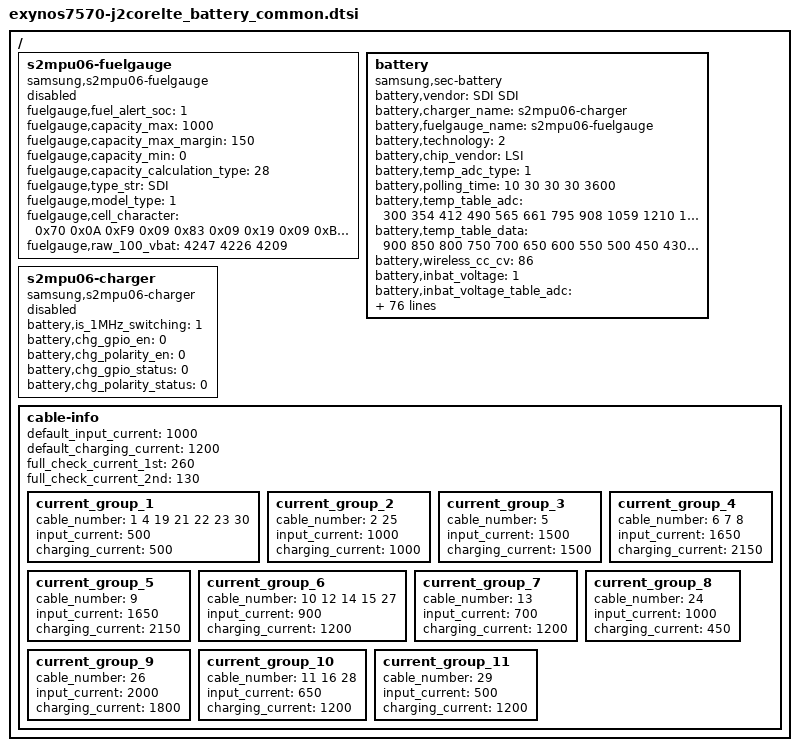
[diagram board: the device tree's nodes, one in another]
/*
 * SAMSUNG UNIVERSAL7570 board device tree source
 *
 * Copyright (c) 2018 Samsung Electronics Co., Ltd.
 *		http://www.samsung.com
 *
 * This program is free software; you can redistribute it and/or modify
 * it under the terms of the GNU General Public License version 2 as
 * published by the Free Software Foundation.
*/

/ {
	s2mpu06-fuelgauge {
		status = "disable";
		compatible = "samsung,s2mpu06-fuelgauge";
		fuelgauge,fuel_alert_soc = <1>;
		fuelgauge,capacity_max = <1000>;
		fuelgauge,capacity_max_margin = <150>;
		fuelgauge,capacity_min = <0>;
		fuelgauge,capacity_calculation_type = <28>;
		fuelgauge,type_str = "SDI";
		fuelgauge,model_type = <1>;
		fuelgauge,cell_character = < 
				/* 4.30V Cell character*/
				/* Cell character 0 0x34 ~ 0xD7 */
				0x70 0x0A 0xF9 0x09 0x83 0x09 0x19 0x09 0xB3 0x08
				0x5A 0x08 0xE6 0x07 0xAE 0x07 0x67 0x07 0xFE 0x06
				0xBB 0x06 0x8F 0x06 0x6C 0x06 0x52 0x06 0x3D 0x06
				0x29 0x06 0x01 0x06 0xD6 0x05 0x95 0x05 0x81 0x05
				0x59 0x04 0x2B 0x03 0x6A 0x08 0x00 0x08 0x95 0x07
				0x2B 0x07 0xC0 0x06 0x56 0x06 0xEB 0x05 0x81 0x05
				0x16 0x05 0xAC 0x04 0x41 0x04 0xD7 0x03 0x6C 0x03
				0x02 0x03 0x97 0x02 0x2D 0x02 0xC2 0x01 0x58 0x01
				0xED 0x00 0x83 0x00 0x18 0x00 0xF5 0x0F 0xFE 0x29
				0xDC 0x29 0x8A 0x29 0x4D 0x29 0x28 0x1F 0x23 0x10
				0x21 0x21 0x14 0x21 0xE9 0xF7 0xE6 0xF7 0xD3 0xDE
				0xCA 0xD4 0xD3 0xD4 0x40 0x80 0x26 0x33 0x26 0x40
				0x26 0x5C 0x26 0x5C 0x26 0x5C 0xFF 0xFF 0x02 0x05
				0x14 0x0B 0x03 0x12 0x06 0x1C 0x0C 0x1C 0x10 0x1C
				0x1F 0x1F 0x40 0x40 0x40 0x40 0x40 0x40 0x41 0x41
				0x40 0x40 0x40 0x41 0x42 0x43 0x44 0x46 0x47 0x4B
				0x51 0x62 0x88 0x80

				/* Cell character 1, 0x0F ~ 0x13 */
				0xEC 0x28 0x0A 0x00 0x00

				/* 4.28V Cell character*/
				/* Cell character 0, 0x34 ~ 0xD7 */
				0x3E 0x0A 0xCF 0x09 0x60 0x09 0xFC 0x08 0xA3 0x08
				0x3B 0x08 0xDF 0x07 0xA8 0x07 0x66 0x07 0x00 0x07
				0xBE 0x06 0x93 0x06 0x71 0x06 0x56 0x06 0x40 0x06
				0x33 0x06 0x11 0x06 0xED 0x05 0xB8 0x05 0x88 0x05
				0x60 0x05 0x20 0x03 0x68 0x08 0x00 0x08 0x98 0x07
				0x2F 0x07 0xC7 0x06 0x5F 0x06 0xF6 0x05 0x8E 0x05
				0x26 0x05 0xBD 0x04 0x55 0x04 0xED 0x03 0x84 0x03
				0x1C 0x03 0xB4 0x02 0x4B 0x02 0xE3 0x01 0x7A 0x01
				0x12 0x01 0xAA 0x00 0x42 0x00 0xDF 0x0F 0xFE 0x29
				0xDC 0x29 0x8A 0x29 0x4D 0x29 0x28 0x1F 0x23 0x10
				0x21 0x21 0x14 0x21 0xE9 0xF7 0xE6 0xF7 0xD3 0xDE
				0xCA 0xD4 0xD3 0xD4 0x40 0x80 0x26 0x33 0x26 0x40
				0x26 0x5C 0x26 0x5C 0x26 0x5C 0xFF 0xFF 0x02 0x05
				0x14 0x0B 0x03 0x12 0x06 0x1C 0x0C 0x1C 0x10 0x1C
				0x1F 0x1F 0x44 0x44 0x45 0x45 0x45 0x44 0x46 0x46
				0x45 0x46 0x46 0x47 0x48 0x4A 0x4B 0x4D 0x4F 0x54
				0x5D 0x6F 0x92 0xD6

				/* Cell character 1, 0x0F ~ 0x13 */
				0xEC 0x33 0x09 0x00 0x00

				/* 4.26V Cell character*/
				/* Cell character 0, 0x34 ~ 0xD7 */
				0xAB 0x09 0x42 0x09 0xE2 0x08 0x94 0x08 0x20 0x08
				0xDA 0x07 0xA1 0x07 0x60 0x07 0xFB 0x06 0xBE 0x06
				0x94 0x06 0x73 0x06 0x59 0x06 0x43 0x06 0x35 0x06
				0x17 0x06 0xF5 0x05 0xC6 0x05 0x8D 0x05 0x7F 0x05
				0x49 0x04 0xC3 0x02 0x00 0x08 0x9B 0x07 0x35 0x07
				0xD0 0x06 0x6B 0x06 0x05 0x06 0xA0 0x05 0x3B 0x05
				0xD5 0x04 0x70 0x04 0x0A 0x04 0xA5 0x03 0x40 0x03
				0xDA 0x02 0x75 0x02 0x10 0x02 0xAA 0x01 0x45 0x01
				0xDF 0x00 0x7A 0x00 0x15 0x00 0xEC 0x0F 0xFE 0x29
				0xDC 0x29 0x8A 0x29 0x4D 0x29 0x28 0x1F 0x23 0x10
				0x21 0x21 0x14 0x21 0xE9 0xF7 0xE6 0xF7 0xD3 0xDE
				0xCA 0xD4 0xD3 0xD4 0x40 0x80 0x26 0x33 0x26 0x40
				0x26 0x5C 0x26 0x5C 0x26 0x5C 0xFF 0xFF 0x02 0x05
				0x14 0x0B 0x03 0x12 0x06 0x1C 0x0C 0x1C 0x10 0x1C
				0x1F 0x1F 0x43 0x43 0x43 0x44 0x44 0x45 0x44 0x44
				0x45 0x45 0x46 0x47 0x49 0x4A 0x4C 0x4D 0x51 0x58
				0x63 0x7D 0xAF 0xC0

				/* Cell character 1, 0x0F ~ 0x13 */ 
				0xEC 0x1F 0x09 0x00 0x00
				>;

				fuelgauge,raw_100_vbat = <4247 4226 4209>;
	};

	battery {
		status = "okay";

		pinctrl-names = "default";

		compatible = "samsung,sec-battery";
		battery,vendor = "SDI SDI";
		battery,charger_name = "s2mpu06-charger";
		battery,fuelgauge_name = "s2mpu06-fuelgauge";
		battery,technology = <2>; /* POWER_SUPPLY_TECHNOLOGY_LION */

		battery,chip_vendor = "LSI";

		battery,temp_adc_type = <1>; /* SEC_BATTERY_ADC_TYPE_AP */

		battery,polling_time = <10 30 30 30 3600>;

		battery,temp_table_adc = <300 354 412 490 565 661 795 908 1059 1210 1270 1372 1570 1780 2010
						2240 2495 2726 2925 3126 3242 3324 3469 3591 3689>;

		battery,temp_table_data = <900 850 800 750 700 650 600 550 500 450 430 400 350 300 250
						200 150 100 50 0 (-30) (-50) (-100) (-150) (-200)>;

		battery,wireless_cc_cv = <86>;
		battery,inbat_voltage = <1>;

		battery,inbat_voltage_table_adc = <
						2789 2781 2764 2747 2737 2706 2698 2678 2656 2627
						2608 2601 2584 2565 2556 2545 2540 2528 2514 2505
						2491 2483 2472 2453 2437 2419 2398 2374 2365 2348
						2319 2286
						>;

		battery,inbat_voltage_table_data = <
						4350 4330 4300 4270 4250 4200 4180 4140 4100 4050
						4010 4000 3980 3950 3930 3910 3900 3880 3860 3840
						3810 3800 3780 3750 3720 3680 3640 3600 3580 3550
						3500 3450
						>;

		battery,adc_check_count = <5>;

		battery,cable_check_type = <4>; /* SEC_BATTERY_CABLE_CHECK_PSY */
		battery,cable_source_type = <1>; /* SEC_BATTERY_CABLE_SOURCE_EXTERNAL */
		battery,polling_type = <1>; /* SEC_BATTERY_MONITOR_ALARM */
		battery,monitor_initial_count = <0>;

		battery,battery_check_type = <5>; /* SEC_BATTERY_CHECK_CHARGER */
		battery,check_count = <0>;

		battery,ovp_uvlo_check_type = <3>; /* SEC_BATTERY_OVP_UVLO_CHGPOLLING */

		battery,check_adc_max = <1440>;
		battery,check_adc_min = <0>;

		battery,thermal_source = <2>; /* SEC_BATTERY_THERMAL_SOURCE_ADC */

		battery,temp_check_type = <2>; /* SEC_BATTERY_TEMP_CHECK_TEMP */
		battery,temp_check_count = <1>;
		battery,temp_highlimit_threshold_normal = <800>;
		battery,temp_highlimit_recovery_normal = <750>;
		battery,temp_high_threshold_normal = <500>;
		battery,temp_high_recovery_normal = <450>;
		battery,temp_low_threshold_normal = <0>;
		battery,temp_low_recovery_normal = <50>;
		battery,temp_highlimit_threshold_lpm = <800>;
		battery,temp_highlimit_recovery_lpm = <750>;
		battery,temp_high_threshold_lpm = <500>;
		battery,temp_high_recovery_lpm = <450>;
		battery,temp_low_threshold_lpm = <0>;
		battery,temp_low_recovery_lpm = <50>;

		battery,full_check_type = <7>; /* SEC_BATTERY_FULLCHARGED_CHGPSY */
		battery,full_check_type_2nd = <7>; /* SEC_BATTERY_FULLCHARGED_CHGPSY */
		battery,full_check_count = <1>;
		battery,chg_gpio_full_check = <0>;
		battery,chg_polarity_full_check = <1>;

		battery,chg_high_temp_1st = <530>;
		battery,chg_high_temp_2nd = <530>;
		battery,chg_high_temp_recovery = <525>;
		battery,chg_charging_limit_current = <1300>;
		battery,chg_charging_limit_current_2nd = <1300>;
		battery,chg_skip_check_capacity = <10>;
		battery,chg_skip_check_time = <600>;

		battery,wpc_high_temp = <420>;
		battery,wpc_high_temp_recovery = <410>;
		battery,wpc_charging_limit_current = <450>;

		/* SEC_BATTERY_FULL_CONDITION_SOC |
		   SEC_BATTERY_FULL_CONDITION_NOTIMEFULL |
		   SEC_BATTERY_FULL_CONDITION_VCELL */
		battery,full_condition_type = <15>;
		battery,full_condition_soc = <93>;
		battery,full_condition_vcell = <4200>;

		battery,recharge_check_count = <2>;
		battery,recharge_condition_type = <4>; /* SEC_BATTERY_RECHARGE_CONDITION_VCELL */
		battery,recharge_condition_soc = <98>;
		battery,recharge_condition_vcell = <4200>;

		battery,standard_curr = <1045>; /* inefficient charging case */
		battery,recharging_expired_time = <5400>;
		battery,expired_time = <16800>; /* 200 + 80 = 280*60 in seconds  */

		battery,chg_float_voltage = <4300>;

		/* cycle(week), chg_float_voltage, recharge_condition_vcell, full_condition_vcell, full_condition_soc*/
		battery,age_data = <0 4300 4200 4200 93
				28 4280 4180 4180 91
				36 4260 4160 4160 89>;

		battery,swelling_high_temp_block = <410>;
		battery,swelling_high_temp_recov = <390>;

		battery,swelling_low_temp_2step_mode = <1>;
		battery,swelling_low_temp_block_1st = <150>;
		battery,swelling_low_temp_recov_1st = <200>;
		battery,swelling_low_temp_block_2nd = <50>;
		battery,swelling_low_temp_recov_2nd = <100>;

		battery,swelling_low_temp_current = <740>;	/* 0.3C */
		battery,swelling_low_temp_topoff = <130>;	/* 0.05C */
		battery,swelling_high_temp_current = <1120>;	/* 0.45C */
		battery,swelling_high_temp_topoff = <130>;	/* 0.05C */

		battery,swelling_drop_float_voltage = <4100>;
		battery,swelling_high_rechg_voltage = <3950>;
		battery,swelling_low_rechg_voltage = <3950>;

        battery,charging_by_single;
        battery,call_event_siop_level = <100>;

        battery,call_event_input = <1200>;
        battery,call_event_output = <720>;

		io-channels = <&exynos_adc 1>, <&exynos_adc 5>;
		io-channel-names = "adc-temp", "adc-in-bat";
		#io-channel-cells = <2>;
		io-channel-ranges;
	};

	s2mpu06-charger {
		status = "disable";
		compatible = "samsung,s2mpu06-charger";
		battery,is_1MHz_switching = <1>;
		battery,chg_gpio_en = <0>;
		battery,chg_polarity_en = <0>;
		battery,chg_gpio_status = <0>;
		battery,chg_polarity_status = <0>;
	};

/* sec_battery_cable
 *   0	UNKNOWN,
 *   1	NONE,
 *   2	PREPARE_TA,
 *   3	TA,
 *   4	USB,
 *   5	USB_CDP,
 *   6	9V_TA,
 *   7	9V_ERR,
 *   8	9V_UNKNOWN,
 *   9	12V_TA,
 *  10	WIRELESS,
 *  11	HV_WIRELESS,
 *  12	PMA_WIRELESS,
 *  13	WIRELESS_PACK,
 *  14	WIRELESS_PACK_TA,
 *  15	WIRELESS_STAND,
 *  16	WIRELESS_HV_STAND,
 *  17	QC20,
 *  18	QC30,
 *  19	PDIC,
 *  20	UARTOFF,
 *  21	OTG,
 *  22	LAN_HUB,
 *  23	POWER_SHARING,
 *  24	HMT_CONNECTED,
 *  25	HMT_CHARGE,
 *  26	HV_TA_CHG_LIMIT,
 *  27	WIRELESS_VEHICLE,
 *  28	WIRELESS_HV_VEHICLE,
 *  29	PREPARE_WIRELESS_HV,
 *  30	TIMEOUT,
 *  31	CABLE_MAX,
 */
	cable-info {
		default_input_current = <1000>;
		default_charging_current = <1200>;
		full_check_current_1st = <260>;
		full_check_current_2nd = <130>;

		current_group_1 {
			cable_number = <1 4 19 21 22 23 30>;
			input_current = <500>;
			charging_current = <500>;
		};

		current_group_2 {
			cable_number = <2 25>;
			input_current = <1000>;
			charging_current = <1000>;
		};

		current_group_3 {
			cable_number = <5>;
			input_current = <1500>;
			charging_current = <1500>;
		};

		current_group_4 {
			cable_number = <6 7 8>;
			input_current = <1650>;
			charging_current = <2150>;
		};

		current_group_5 {
			cable_number = <9>;
			input_current = <1650>;
			charging_current = <2150>;
		};

		current_group_6 {
			cable_number = <10 12 14 15 27>;
			input_current = <900>;
			charging_current = <1200>;
		};

		current_group_7 {
			cable_number = <13>;
			input_current = <700>;
			charging_current = <1200>;
		};

		current_group_8 {
			cable_number = <24>;
			input_current = <1000>;
			charging_current = <450>;
		};

		current_group_9 {
			cable_number = <26>;
			input_current = <2000>;
			charging_current = <1800>;
		};

		current_group_10 {
			cable_number = <11 16 28>;
			input_current = <650>;
			charging_current = <1200>;
		};

		current_group_11 {
			cable_number = <29>;
			input_current = <500>;
			charging_current = <1200>;
		};
	};
};

